# STM32L0x3 register map
File version: 1.7
CPU: CM0+ r0p0, little endian, MPU, no FPU, 2 interrupt priority bits
Registers are 32-bit, read-write, reset 0x0 unless marked. A register's access mark holds for its fields unless they carry their own. Offsets are from the block's base; [hi:lo] are bit positions; {n}, {i} and the like mark numbered series; 'fields as' and 'values as' point back to an identical list.

## ADC — Analog-to-digital converter
Base 0x40012400
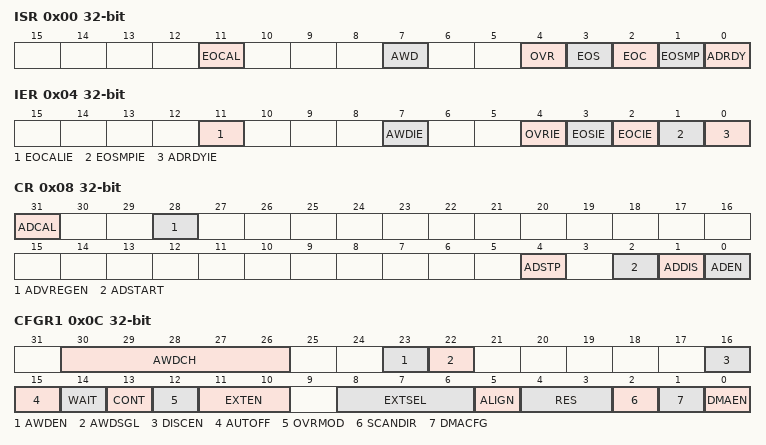
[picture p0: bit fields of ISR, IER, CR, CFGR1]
0x00 ISR — interrupt and status register
  [11] EOCAL write-1-clears — End Of Calibration flag
    on read: 0=NotComplete (Calibration is not complete); 1=Complete (Calibration complete) | on write: 1=Clear the calibration flag
  [7] AWD write-1-clears — Analog watchdog flag
    on read: 0=NoEvent (No analog watchdog event occurred); 1=Event (Analog watchdog event occurred) | on write: 1=Clear the analog watchdog event flag
  [4] OVR write-1-clears — ADC overrun
    on read: 0=No overrun occurred; 1=Overrun occurred | on write: 1=Clear the overrun flag
  [3] EOS write-1-clears — End of sequence flag
    on read: 0=NotComplete (Conversion sequence is not complete); 1=Complete (Conversion sequence complete) | on write: 1=Clear the conversion sequence flag
  [2] EOC write-1-clears — End of conversion flag
    on read: 0=NotComplete (Channel conversion is not complete); 1=Complete (Channel conversion complete) | on write: 1=Clear the channel conversion flag
  [1] EOSMP write-1-clears — End of sampling flag
    on read: 0=NotAtEnd (Not at the end of the samplings phase); 1=AtEnd (End of sampling phase reached) | on write: 1=Clear the sampling phase flag
  [0] ADRDY write-1-clears — ADC ready
    on read: 0=NotReady (ADC not yet ready to start conversion); 1=Ready (ADC ready to start conversion) | on write: 1=Clear the ADC ready flag
0x04 IER — interrupt enable register
  [11] EOCALIE — End of calibration interrupt enable
    0=Disabled (End of calibration interrupt disabled); 1=Enabled (End of calibration interrupt enabled)
  [7] AWDIE — Analog watchdog interrupt enable
    0=Disabled (Analog watchdog interrupt disabled); 1=Enabled (Analog watchdog interrupt enabled)
  [4] OVRIE — Overrun interrupt enable
    0=Disabled (Overrun interrupt disabled); 1=Enabled (Overrun interrupt enabled. An interrupt is generated when the OVR bit is set.)
  [3] EOSIE — End of conversion sequence interrupt enable
    0=Disabled (EOS interrupt disabled); 1=Enabled (EOS interrupt enabled. An interrupt is generated when the EOS bit is set.)
  [2] EOCIE — End of conversion interrupt enable
    0=Disabled (EOC interrupt disabled); 1=Enabled (EOC interrupt enabled. An interrupt is generated when the EOC bit is set.)
  [1] EOSMPIE — End of sampling flag interrupt enable
    0=Disabled (EOSMP interrupt disabled); 1=Enabled (EOSMP interrupt enabled. An interrupt is generated when the EOSMP bit is set.)
  [0] ADRDYIE — ADC ready interrupt enable
    0=Disabled (ADRDY interrupt disabled); 1=Enabled (ADRDY interrupt enabled. An interrupt is generated when the ADRDY bit is set.)
0x08 CR — control register
  [31] ADCAL write-1-sets — ADC calibration
    on read: 0=NotCalibrating (ADC calibration either not yet performed or completed); 1=Calibrating (ADC calibration in progress) | on write: 1=StartCalibration (Start the ADC calibration sequence)
  [28] ADVREGEN — ADC Voltage Regulator Enable
    0=Disabled (ADC voltage regulator disabled); 1=Enabled (ADC voltage regulator enabled)
  [4] ADSTP write-1-sets — ADC stop conversion command
    on read: 0=NotStopping (No stop command active); 1=Stopping (ADC stopping conversion) | on write: 1=StopConversion (Stop the active conversion)
  [2] ADSTART write-1-sets — ADC start conversion command
    on read: 0=NotActive (No conversion ongoing); 1=Active (ADC operating and may be converting) | on write: 1=StartConversion (Start the ADC conversion (may be delayed for hardware triggers))
  [1] ADDIS write-1-sets — ADC disable command
    on read: 0=NotDisabling (No disable command active); 1=Disabling (ADC disabling) | on write: 1=Disable the ADC
  [0] ADEN write-1-sets — ADC enable command
    on read: 0=Disabled (ADC disabled); 1=Enabled (ADC enabled) | on write: 1=Enabled (Enable the ADC)
0x0C CFGR1 — configuration register 1
  [30:26] AWDCH range 0..18 — Analog watchdog channel selection
  [23] AWDEN — Analog watchdog enable
    0=Disabled (Analog watchdog disabled); 1=Enabled (Analog watchdog enabled)
  [22] AWDSGL — Enable the watchdog on a single channel or on all channels
    0=AllChannels (Analog watchdog enabled on all channels); 1=SingleChannel (Analog watchdog enabled on a single channel)
  [16] DISCEN — Discontinuous mode
    0=Disabled (Discontinuous mode disabled); 1=Enabled (Discontinuous mode enabled)
  [15] AUTOFF — Auto-off mode
    0=Disabled (Auto-off mode disabled); 1=Enabled (Auto-off mode enabled)
  [14] WAIT — Auto-delayed conversion mode
    0=Disabled (Wait conversion mode off); 1=Enabled (Wait conversion mode on)
  [13] CONT — Single / continuous conversion mode
    0=Single conversion mode; 1=Continuous conversion mode
  [12] OVRMOD — Overrun management mode
    0=Preserve (ADC_DR register is preserved with the old data when an overrun is detected); 1=Overwrite (ADC_DR register is overwritten with the last conversion result when an overrun is detected)
  [11:10] EXTEN — External trigger enable and polarity selection
    0=Disabled (Hardware trigger detection disabled); 1=RisingEdge (Hardware trigger detection on the rising edge); 2=FallingEdge (Hardware trigger detection on the falling edge); 3=BothEdges (Hardware trigger detection on both the rising and falling edges)
  [8:6] EXTSEL — External trigger selection
    0=TIM6_TRGO (Timer 6 TRGO event); 1=TIM21_CH2 (Timer 21 CH2 event); 2=TIM2_TRGO (Timer 2 TRGO event); 3=TIM2_CH4 (Timer 2 CH4 event); 4=TIM22_TRGO (Timer 22 TRGO, Timer 21 TRGO event); 5=TIM2_CH3 (Timer 2 CH3 event); 6=TIM3_TRGO (Timer 3 TRGO event); 7=EXTI_LINE11 (EXTI line 11 event)
  [5] ALIGN — Data alignment
    0=Right alignment; 1=Left alignment
  [4:3] RES — Data resolution
    0=TwelveBit (12 bits); 1=TenBit (10 bits); 2=EightBit (8 bits); 3=SixBit (6 bits)
  [2] SCANDIR — Scan sequence direction
    0=Upward scan (from CHSEL0 to CHSEL18); 1=Backward scan (from CHSEL18 to CHSEL0)
  [1] DMACFG — Direct memery access configuration
    0=OneShot (DMA one shot mode selected); 1=Circular (DMA circular mode selected)
  [0] DMAEN — Direct memory access enable
    0=Disabled (DMA disabled); 1=Enabled (DMA enabled)
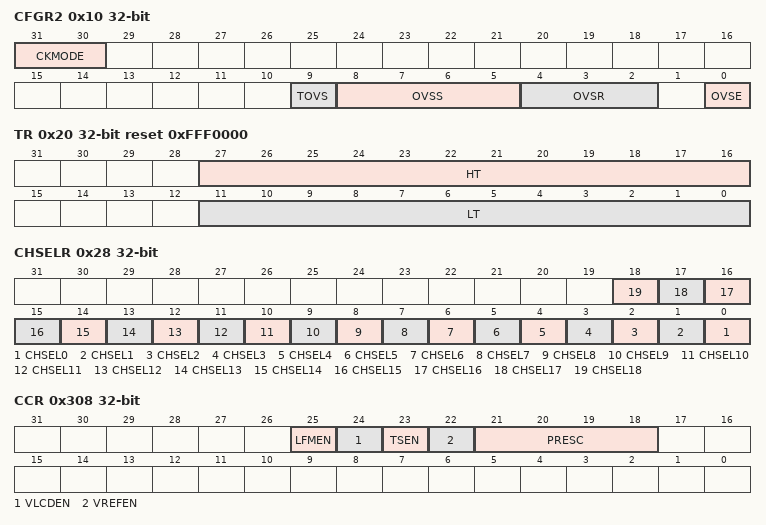
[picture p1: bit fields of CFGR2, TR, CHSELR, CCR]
0x10 CFGR2 — configuration register 2
  [31:30] CKMODE — ADC clock mode
    0=ADCLK (ADCCLK (Asynchronous clock mode)); 1=PCLK_Div2 (PCLK/2 (Synchronous clock mode)); 2=PCLK_Div4 (PCLK/4 (Synchronous clock mode)); 3=PCLK (PCLK (Synchronous clock mode))
  [9] TOVS — Triggered Oversampling
    0=TriggerAll (All oversampled conversions for a channel are done consecutively after a trigger); 1=TriggerEach (Each oversampled conversion for a channel needs a trigger)
  [8:5] OVSS range 0..8 — Oversampling shift
  [4:2] OVSR — Oversampling ratio
    0=Mul2 (2x); 1=Mul4 (4x); 2=Mul8 (8x); 3=Mul16 (16x); 4=Mul32 (32x); 5=Mul64 (64x); 6=Mul128 (128x); 7=Mul256 (256x)
  [0] OVSE — Oversampler Enable
    0=Disabled (Oversampler disabled); 1=Enabled (Oversampler enabled)
0x14 SMPR — sampling time register
  [2:0] SMP — Sampling time selection
    0=Cycles1_5 (1.5 ADC clock cycles); 1=Cycles3_5 (3.5 ADC clock cycles); 2=Cycles7_5 (7.5 ADC clock cycles); 3=Cycles12_5 (12.5 ADC clock cycles); 4=Cycles19_5 (19.5 ADC clock cycles); 5=Cycles39_5 (39.5 ADC clock cycles); 6=Cycles79_5 (79.5 ADC clock cycles); 7=Cycles160_5 (160.5 ADC clock cycles)
0x20 TR reset 0xFFF0000 — watchdog threshold register
  [27:16] HT range 0..2047 — Analog watchdog higher threshold
  [11:0] LT range 0..2047 — Analog watchdog lower threshold
0x28 CHSELR — channel selection register
  [n] CHSEL{n} (n=0..18) — Channel-x selection
    0=NotSelected (Input Channel is not selected for conversion); 1=Selected (Input Channel is selected for conversion)
0x40 DR ro — data register
  [15:0] DATA — Converted data
0xB4 CALFACT — ADC Calibration factor
  [6:0] CALFACT — Calibration factor
0x308 CCR — ADC common configuration register
  [25] LFMEN — Low Frequency Mode enable
    0=Disabled (Low Frequency Mode disabled); 1=Enabled (Low Frequency Mode enabled)
  [24] VLCDEN — VLCD reading circuitry enable
    0=Disabled (VLCD reading circuitry disabled); 1=Enabled (VLCD reading circuitry enabled)
  [23] TSEN — Temperature sensor enable
    0=Disabled (The selected ADC channel disabled); 1=Enabled (The selected ADC channel enabled)
  [22] VREFEN — VREFINT enable
    values as TSEN
  [21:18] PRESC — ADC prescaler
    0=Div1 (Input ADC clock not divided); 1=Div2 (Input ADC clock divided by 2); 2=Div4 (Input ADC clock divided by 4); 3=Div6 (Input ADC clock divided by 6); 4=Div8 (Input ADC clock divided by 8); 5=Div10 (Input ADC clock divided by 10); 6=Div12 (Input ADC clock divided by 12); 7=Div16 (Input ADC clock divided by 16); 8=Div32 (Input ADC clock divided by 32); 9=Div64 (Input ADC clock divided by 64); 10=Div128 (Input ADC clock divided by 128); 11=Div256 (Input ADC clock divided by 256)
